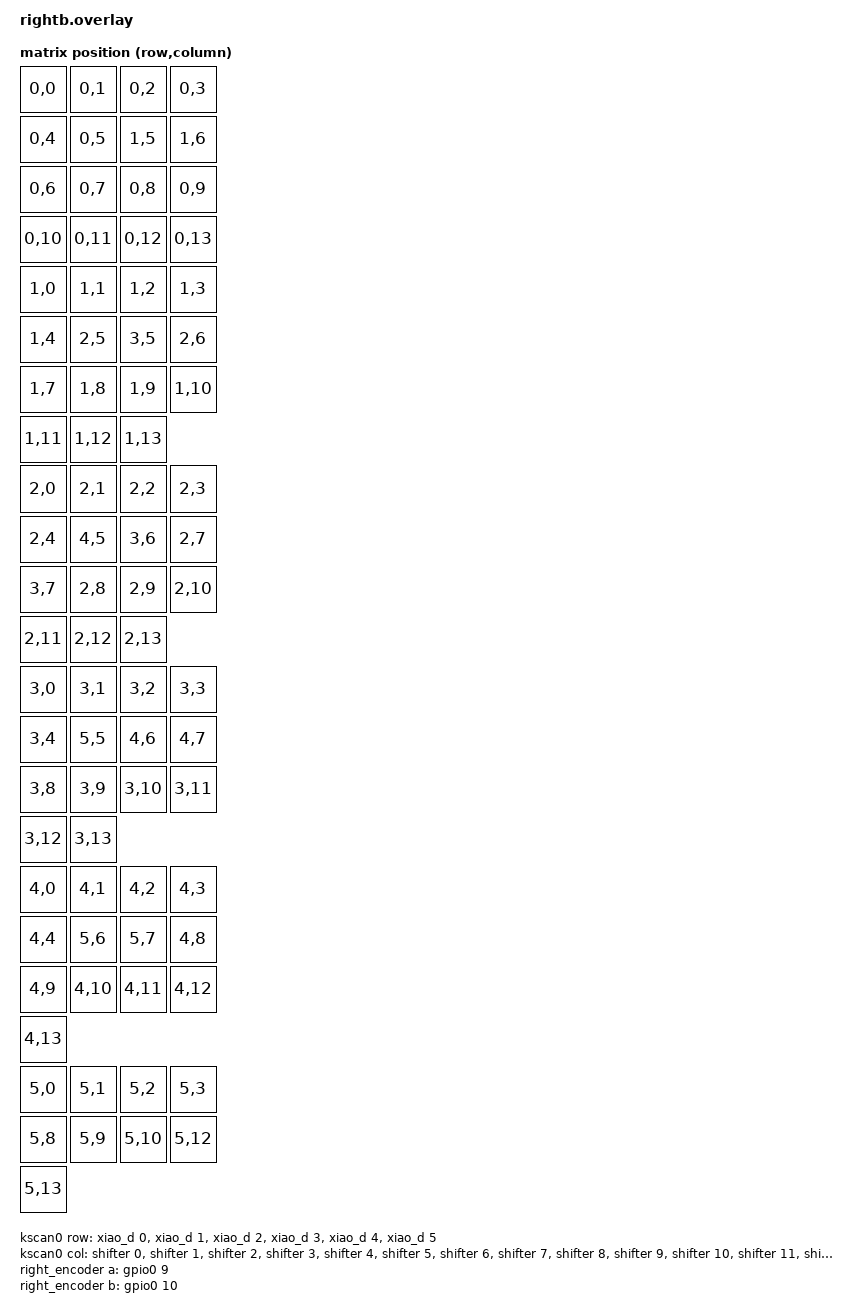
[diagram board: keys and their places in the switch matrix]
// This file was generated from a template. Edit it to match your keyboard.
// See https://zmk.dev/docs/development/hardware-integration/new-shield for more
// instructions.

#include <dt-bindings/zmk/matrix_transform.h>

#include "rightb-layouts.dtsi"

/ {
    chosen {
        zmk,physical-layout = &physical_layout0;
    };

    kscan0: kscan {
        // If the hardware does not use a switch matrix, change this to the
        // appropriate driver and update the properties below to match.
        // See https://zmk.dev/docs/config/kscan for supported key scan drivers.
        compatible = "zmk,kscan-gpio-matrix";
        // Set this to "col2row" or "row2col" to match the hardware. If using
        // "row2col", change the col-gpios to (GPIO_ACTIVE_HIGH | GPIO_PULL_DOWN)
        // and the row-gpios to GPIO_ACTIVE_HIGH.
        diode-direction = "col2row";
        wakeup-source;

        // Replace these comments with the GPIO pins in the matrix.
        // See https://zmk.dev/docs/development/hardware-integration/new-shield#shield-overlays
        col-gpios
            = <&shifter 0 GPIO_ACTIVE_HIGH>
            , <&shifter 1 GPIO_ACTIVE_HIGH>
            , <&shifter 2 GPIO_ACTIVE_HIGH>
            , <&shifter 3 GPIO_ACTIVE_HIGH>
            , <&shifter 4 GPIO_ACTIVE_HIGH>
            , <&shifter 5 GPIO_ACTIVE_HIGH>
            , <&shifter 6 GPIO_ACTIVE_HIGH>
            , <&shifter 7 GPIO_ACTIVE_HIGH>
            , <&shifter 8 GPIO_ACTIVE_HIGH>
            , <&shifter 9 GPIO_ACTIVE_HIGH>
            , <&shifter 10 GPIO_ACTIVE_HIGH>
            , <&shifter 11 GPIO_ACTIVE_HIGH>
            , <&shifter 12 GPIO_ACTIVE_HIGH>
            , <&shifter 13 GPIO_ACTIVE_HIGH>
            ;

        row-gpios
            = <&xiao_d 0 (GPIO_ACTIVE_HIGH | GPIO_PULL_DOWN)>
            , <&xiao_d 1 (GPIO_ACTIVE_HIGH | GPIO_PULL_DOWN)>
            , <&xiao_d 2 (GPIO_ACTIVE_HIGH | GPIO_PULL_DOWN)>
            , <&xiao_d 3 (GPIO_ACTIVE_HIGH | GPIO_PULL_DOWN)>
            , <&xiao_d 4 (GPIO_ACTIVE_HIGH | GPIO_PULL_DOWN)>
            , <&xiao_d 5 (GPIO_ACTIVE_HIGH | GPIO_PULL_DOWN)>
            ;
    };

    matrix_transform0: matrix_transform {
        // See https://zmk.dev/docs/development/hardware-integration/new-shield#matrix-transform
        // for how to configure this
        compatible = "zmk,matrix-transform";
        columns = <14>;
        rows = <6>;

        map = <
            /* Esc F1 F2 F3 F4 F5 F6 F7 F8 F9 F10 F11 F12 PrtSc Delete Encoder */
            RC(0,0)   RC(0,1)   RC(0,2)   RC(0,3)
            RC(0,4)   RC(0,5)   RC(1,5)   RC(1,6)
            RC(0,6)   RC(0,7)   RC(0,8)   RC(0,9)
            RC(0,10)  RC(0,11)  RC(0,12)  RC(0,13)

            /* ` 1 2 3 4 5 6 7 8 9 0 - = Backspace Home */
            RC(1,0)   RC(1,1)   RC(1,2)   RC(1,3)
            RC(1,4)   RC(2,5)   RC(3,5)   RC(2,6)
            RC(1,7)   RC(1,8)   RC(1,9)   RC(1,10)
            RC(1,11)  RC(1,12)  RC(1,13)

            /* Tab Q W E R T Y U I O P [ ] \ End */
            RC(2,0)   RC(2,1)   RC(2,2)   RC(2,3)
            RC(2,4)   RC(4,5)   RC(3,6)   RC(2,7)
            RC(3,7)   RC(2,8)   RC(2,9)   RC(2,10)
            RC(2,11)  RC(2,12)  RC(2,13)

            /* Caps A S D F G H J K L ; ' Enter Up */
            RC(3,0)   RC(3,1)   RC(3,2)   RC(3,3)
            RC(3,4)   RC(5,5)   RC(4,6)   RC(4,7)
            RC(3,8)   RC(3,9)   RC(3,10)  RC(3,11)
            RC(3,12)  RC(3,13)

            /* LShift Z X C V B N M , . / RShift Down */
            RC(4,0)   RC(4,1)   RC(4,2)   RC(4,3)
            RC(4,4)   RC(5,6)   RC(5,7)   RC(4,8)
            RC(4,9)   RC(4,10)  RC(4,11)  RC(4,12)
            RC(4,13)

            /* LCtrl LGui LAlt LSpace RSpace Fn1 Fn2 Left Right */
            RC(5,0)   RC(5,1)   RC(5,2)   RC(5,3)
            RC(5,8)   RC(5,9)   RC(5,10)  RC(5,12)
            RC(5,13)
        >;
    };

    right_encoder: encoder_right {
        compatible = "alps,ec11";
        a-gpios = <&gpio0 9 (GPIO_ACTIVE_HIGH | GPIO_PULL_UP)>;
        b-gpios = <&gpio0 10 (GPIO_ACTIVE_HIGH | GPIO_PULL_UP)>;
        steps = <24>;
        status = "okay";
    };

    sensors: sensors {
        compatible = "zmk,keymap-sensors";
        sensors = <&right_encoder>;
        triggers-per-rotation = <24>;
    };
};

&xiao_spi {
    status = "okay";
    cs-gpios = <&xiao_d 6 GPIO_ACTIVE_LOW>;
    shifter: 595@0 {
        compatible = "zmk,gpio-595";
        status = "okay";
        gpio-controller;
        spi-max-frequency = <4000000>;   // 4 MHz
        reg = <0>;
        #gpio-cells = <2>;
        ngpios = <16>;
    };
};
